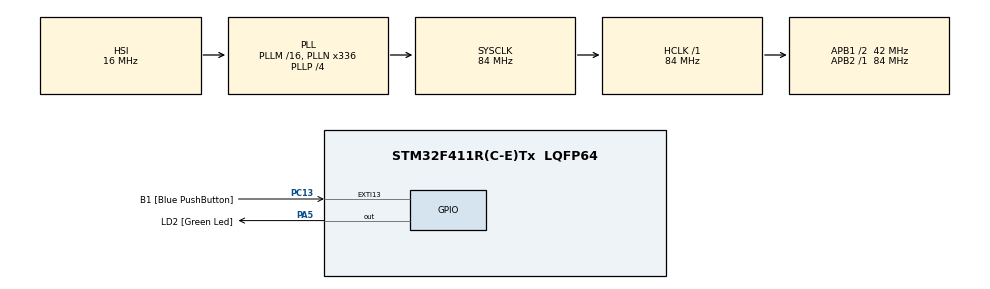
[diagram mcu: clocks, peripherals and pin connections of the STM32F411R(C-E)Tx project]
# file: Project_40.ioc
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FREERTOS.Tasks01=defaultTask,0,128,StartDefaultTask,Default,NULL,Dynamic,NULL,NULL
Mcu.Family=STM32F4
Mcu.Name=STM32F411R(C-E)Tx
Mcu.Package=LQFP64
NVIC.PriorityGroup=NVIC_PRIORITYGROUP_4
PA5.GPIO_Label=LD2 [Green Led]
PA5.Signal=GPIO_Output
PC13-ANTI_TAMP.GPIO_Label=B1 [Blue PushButton]
PC13-ANTI_TAMP.GPIO_ModeDefaultEXTI=GPIO_MODE_IT_FALLING
PC13-ANTI_TAMP.Signal=GPXTI13
ProjectManager.HeapSize=0x200
ProjectManager.StackSize=0x400
ProjectManager.TargetToolchain=MDK-ARM V5.27
RCC.48MHZClocksFreq_Value=84000000
RCC.AHBFreq_Value=84000000
RCC.APB1CLKDivider=RCC_HCLK_DIV2
RCC.APB1Freq_Value=42000000
RCC.APB1TimFreq_Value=84000000
RCC.APB2Freq_Value=84000000
RCC.APB2TimFreq_Value=84000000
RCC.CortexFreq_Value=84000000
RCC.FLatency-AdvancedSettings=FLASH_LATENCY_2
RCC.HCLKFreq_Value=84000000
RCC.HSE_VALUE=8000000
RCC.HSI_VALUE=16000000
RCC.LSE_VALUE=32768
RCC.PLLN=336
RCC.PLLP=RCC_PLLP_DIV4
RCC.SYSCLKFreq_VALUE=84000000
RCC.SYSCLKSource=RCC_SYSCLKSOURCE_PLLCLK
RCC.VCOOutputFreq_Value=336000000
VP_FREERTOS_VS_CMSIS_V1.Mode=CMSIS_V1
board=NUCLEO-F411RE

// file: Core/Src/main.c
/* USER CODE BEGIN Header */
/**
  ******************************************************************************
  * @file           : main.c
  * @brief          : Main program body
  ******************************************************************************
  * @attention
  *
  * <h2><center>&copy; Copyright (c) 2021 STMicroelectronics.
  * All rights reserved.</center></h2>
  *
  * This software component is licensed by ST under Ultimate Liberty license
  * SLA0044, the "License"; You may not use this file except in compliance with
  * the License. You may obtain a copy of the License at:
  *                             www.st.com/SLA0044
  *
  ******************************************************************************
  */
/* USER CODE END Header */
#include "main.h"
#include "cmsis_os.h"

xTaskHandle task1;
xTaskHandle task2;

void SystemClock_Config(void);
static void MX_GPIO_Init(void);
void function_task1(void *);
void function_task2(void *);

int main(void)
{

  /* MCU Configuration--------------------------------------------------------*/

  /* Reset of all peripherals, Initializes the Flash interface and the Systick. */
  HAL_Init();

  /* Configure the system clock */
  SystemClock_Config();

  /* Initialize all configured peripherals */
  MX_GPIO_Init();

  /* Create the thread(s) */
  xTaskCreate(function_task1, "Task1", configMINIMAL_STACK_SIZE, NULL, 7, &task1);
  xTaskCreate(function_task2, "Task2", configMINIMAL_STACK_SIZE, NULL, 7, &task2);

  /* Start scheduler */
  vTaskStartScheduler();

  /* We should never get here as control is now taken by the scheduler */
  /* Infinite loop */
  /* USER CODE BEGIN WHILE */
  while (1);
  /* USER CODE END 3 */
}

void SystemClock_Config(void)
{
  RCC_OscInitTypeDef RCC_OscInitStruct = {0};
  RCC_ClkInitTypeDef RCC_ClkInitStruct = {0};

  /** Configure the main internal regulator output voltage
  */
  __HAL_RCC_PWR_CLK_ENABLE();
  __HAL_PWR_VOLTAGESCALING_CONFIG(PWR_REGULATOR_VOLTAGE_SCALE1);
  /** Initializes the RCC Oscillators according to the specified parameters
  * in the RCC_OscInitTypeDef structure.
  */
  RCC_OscInitStruct.OscillatorType = RCC_OSCILLATORTYPE_HSI;
  RCC_OscInitStruct.HSIState = RCC_HSI_ON;
  RCC_OscInitStruct.HSICalibrationValue = RCC_HSICALIBRATION_DEFAULT;
  RCC_OscInitStruct.PLL.PLLState = RCC_PLL_ON;
  RCC_OscInitStruct.PLL.PLLSource = RCC_PLLSOURCE_HSI;
  RCC_OscInitStruct.PLL.PLLM = 16;
  RCC_OscInitStruct.PLL.PLLN = 336;
  RCC_OscInitStruct.PLL.PLLP = RCC_PLLP_DIV4;
  RCC_OscInitStruct.PLL.PLLQ = 4;
  if (HAL_RCC_OscConfig(&RCC_OscInitStruct) != HAL_OK)
  {
    Error_Handler();
  }
  /** Initializes the CPU, AHB and APB buses clocks
  */
  RCC_ClkInitStruct.ClockType = RCC_CLOCKTYPE_HCLK|RCC_CLOCKTYPE_SYSCLK
                              |RCC_CLOCKTYPE_PCLK1|RCC_CLOCKTYPE_PCLK2;
  RCC_ClkInitStruct.SYSCLKSource = RCC_SYSCLKSOURCE_PLLCLK;
  RCC_ClkInitStruct.AHBCLKDivider = RCC_SYSCLK_DIV1;
  RCC_ClkInitStruct.APB1CLKDivider = RCC_HCLK_DIV2;
  RCC_ClkInitStruct.APB2CLKDivider = RCC_HCLK_DIV1;

  if (HAL_RCC_ClockConfig(&RCC_ClkInitStruct, FLASH_LATENCY_2) != HAL_OK)
  {
    Error_Handler();
  }
}

static void MX_GPIO_Init(void)
{
  GPIO_InitTypeDef GPIO_InitStruct = {0};

  /* GPIO Ports Clock Enable */
  __HAL_RCC_GPIOC_CLK_ENABLE();
  __HAL_RCC_GPIOA_CLK_ENABLE();

  /*Configure GPIO pin Output Level */
  HAL_GPIO_WritePin(LD2_GPIO_Port, LD2_Pin, GPIO_PIN_RESET);

  /*Configure GPIO pin : B1_Pin */
  GPIO_InitStruct.Pin = B1_Pin;
  GPIO_InitStruct.Mode = GPIO_MODE_IT_FALLING;
  GPIO_InitStruct.Pull = GPIO_NOPULL;
  HAL_GPIO_Init(B1_GPIO_Port, &GPIO_InitStruct);

  /*Configure GPIO pin : LD2_Pin */
  GPIO_InitStruct.Pin = LD2_Pin;
  GPIO_InitStruct.Mode = GPIO_MODE_OUTPUT_PP;
  GPIO_InitStruct.Pull = GPIO_NOPULL;
  GPIO_InitStruct.Speed = GPIO_SPEED_FREQ_LOW;
  HAL_GPIO_Init(LD2_GPIO_Port, &GPIO_InitStruct);

}

/* USER CODE BEGIN 4 */

void function_task1(void *param){

	ulTaskNotifyTake(pdFALSE, portMAX_DELAY );

	while(1){

		HAL_GPIO_TogglePin( LD2_GPIO_Port ,LD2_Pin);
		vTaskDelay( pdMS_TO_TICKS(1000) );

	}

}

void function_task2(void *param){

	// wait until the button is pressed
	while(HAL_GPIO_ReadPin(B1_GPIO_Port, B1_Pin) == GPIO_PIN_SET);
	// notify task1
	xTaskNotifyGive(task1);

	while(1);

}

/* USER CODE END 4 */

void Error_Handler(void)
{
  __disable_irq();
  while (1)
  {
  }
}

/************************ (C) COPYRIGHT STMicroelectronics *****END OF FILE****/
